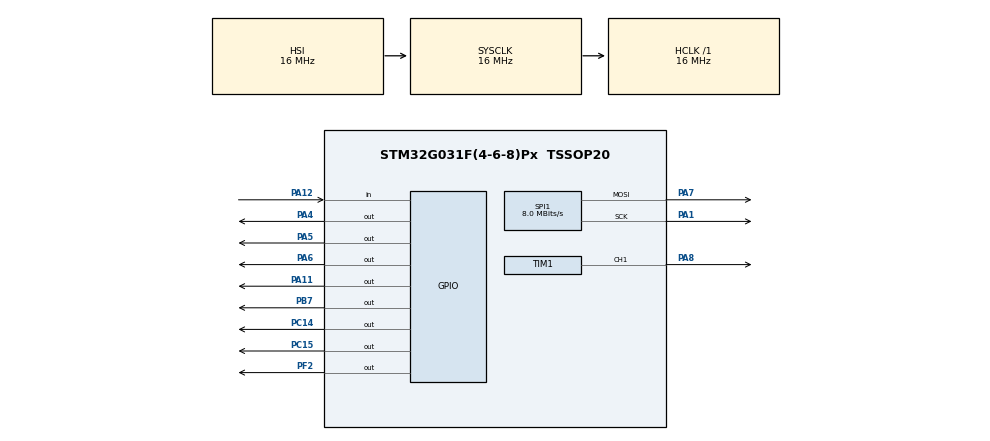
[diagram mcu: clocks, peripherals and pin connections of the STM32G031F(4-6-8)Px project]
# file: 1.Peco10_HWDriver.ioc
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Mcu.Family=STM32G0
Mcu.Name=STM32G031F(4-6-8)Px
Mcu.Package=TSSOP20
NVIC.SPI1_IRQn=true\:0\:0\:false\:false\:true\:true\:true\:true
PA1.Mode=TX_Only_Simplex_Unidirect_Master
PA1.Signal=SPI1_SCK
PA11\ [PA9].Signal=GPIO_Output
PA12\ [PA10].Signal=GPIO_Input
PA14-BOOT0__PA15.StandardMode=true
PA4.Signal=GPIO_Output
PA5.Signal=GPIO_Output
PA6.Signal=GPIO_Output
PA7.Mode=TX_Only_Simplex_Unidirect_Master
PA7.Signal=SPI1_MOSI
PA8.Signal=S_TIM1_CH1
PB0__PB1__PB2__PA8.StandardMode=true
PB3__PB4__PB5__PB6.StandardMode=true
PB7.Signal=GPIO_Output
PB7__PB8.StandardMode=true
PC14-OSC32_IN\ (PC14).Signal=GPIO_Output
PC14-OSC32_IN\ (PC14)__PB9.StandardMode=true
PC15-OSC32_OUT\ (PC15).Signal=GPIO_Output
PF2\ -\ NRST.Signal=GPIO_Output
ProjectManager.HeapSize=0x200
ProjectManager.StackSize=0x400
ProjectManager.TargetToolchain=MDK-ARM V5.32
RCC.AHBFreq_Value=16000000
RCC.CortexFreq_Value=16000000
RCC.EXTERNAL_CLOCK_VALUE=12288000
RCC.HCLKFreq_Value=16000000
RCC.HSE_VALUE=8000000
RCC.HSI_VALUE=16000000
RCC.LSE_VALUE=32768
RCC.SYSCLKFreq_VALUE=16000000
RCC.VCOOutputFreq_Value=128000000
SH.S_TIM1_CH1.0=TIM1_CH1,PWM Generation1 CH1
SPI1.CalculateBaudRate=8.0 MBits/s
SPI1.Direction=SPI_DIRECTION_2LINES
SPI1.Mode=SPI_MODE_MASTER
SPI1.VirtualType=VM_MASTER
TIM1.Channel-PWM\ Generation1\ CH1=TIM_CHANNEL_1
TIM1.Period=999
TIM1.Prescaler=15
TIM1.Pulse-PWM\ Generation1\ CH1=900
TIM2.Prescaler=15
VP_TIM1_VS_ClockSourceINT.Mode=Internal
VP_TIM2_VS_ClockSourceINT.Mode=Internal
board=custom

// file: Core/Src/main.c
/* USER CODE BEGIN Header */
/**
  ******************************************************************************
  * @file           : main.c
  * @brief          : Main program body
  ******************************************************************************
  * @attention
  *
  * Copyright (c) 2022 STMicroelectronics.
  * All rights reserved.
  *
  * This software is licensed under terms that can be found in the LICENSE file
  * in the root directory of this software component.
  * If no LICENSE file comes with this software, it is provided AS-IS.
  *
  ******************************************************************************
  */
/* USER CODE END Header */
#include "main.h"

/* USER CODE BEGIN Includes */
#include "Lcd_character.h"
#include "Lcd_segment.h"
#include "Keypad.h"
#include "Standard.h"
/* USER CODE END Includes */

 SPI_HandleTypeDef hspi1;

TIM_HandleTypeDef htim1;
TIM_HandleTypeDef htim2;

/* USER CODE BEGIN PV */
uint8_t Add_string[]="Address num:";
uint8_t Keypad_string[]="Cur Button:";
uint8_t data0[]="   0,0.0";
uint8_t data1[]="0,00,00";
uint8_t data2[]="1,2.3,456";
/* USER CODE END PV */

void SystemClock_Config(void);
static void MX_GPIO_Init(void);
static void MX_SPI1_Init(void);
static void MX_TIM1_Init(void);
static void MX_TIM2_Init(void);

int main(void)
{

  /* MCU Configuration--------------------------------------------------------*/

  /* Reset of all peripherals, Initializes the Flash interface and the Systick. */
  HAL_Init();

  /* Configure the system clock */
  SystemClock_Config();

  /* Initialize all configured peripherals */
  MX_GPIO_Init();
  MX_SPI1_Init();
  MX_TIM1_Init();
  MX_TIM2_Init();
  /* USER CODE BEGIN 2 */
  uint8_t num[10];
  uint32_t i=0;

  uint8_t key[2];
  Keypad_Button_Type Keypad_status = BUTTON_UNKNOWN;

  uint8_t pDevide_Address[10];
  uint8_t pClear_data[10]="  ";
  uint8_t add,temp;
  temp = 0xff;

  HAL_TIM_Base_Start(&htim2);
  HAL_TIM_PWM_Start(&htim1,TIM_CHANNEL_1);
  Lcd_Init_4bits_Mode();
  Lcd_Segment_Init();

  //Lcd_Segment_Put_Data(data0,0);
  //Lcd_Segment_Put_Data(data1,1);
  //Lcd_Segment_Put_Data(data2,2);
  Lcd_Segment_Put_Indicator(0xf8);
  Lcd_Segment_Display_App();
  Lcd_Put_String(0,0,(uint8_t*)Keypad_string);
  Lcd_Put_String(1,0,(uint8_t*)Add_string);
  //Lcd_Put_String(0,2,(uint8_t*)data);
  /* USER CODE END 2 */

  /* Infinite loop */
  while (1)
  {

    /* USER CODE BEGIN 3 */
    /*Lcd segment test*/
    DecToString(num,i);
    Lcd_Segment_Put_Data(num,0);
    Lcd_Segment_Put_Data(num,1);
    Lcd_Segment_Put_Data(num,2);
    Lcd_Segment_Display_App();

    /*Keypad scaning test*/

    Keypad_status = Keypad_Scan(key);
    if(Keypad_status == KEYPAD_PUSHED)
    {
        Lcd_Put_String(0,strlen((char*)Keypad_string) + 1,(uint8_t*)pClear_data);
        Lcd_Set_Cursor(0,strlen((char*)Keypad_string) + 1);
        Lcd_Put_String(0,strlen((char*)Keypad_string) + 1,(uint8_t*)key);
    }

    /*Switch test*/
    add = Config_Switch_Get_Value();
    if(temp != add)
    {
        DecToString(pDevide_Address,add);
        temp = add;
        Lcd_Put_String(1,strlen((char*)Add_string) + 1,(uint8_t*)pClear_data);
        Lcd_Put_String(1,strlen((char*)Add_string) + 1,(uint8_t*)pDevide_Address);
    }

    mdelay(1);
    i++;
    if(i == 9999999)
        i=0;
  }
  /* USER CODE END 3 */
}

void SystemClock_Config(void)
{
  RCC_OscInitTypeDef RCC_OscInitStruct = {0};
  RCC_ClkInitTypeDef RCC_ClkInitStruct = {0};

  /** Configure the main internal regulator output voltage
  */
  HAL_PWREx_ControlVoltageScaling(PWR_REGULATOR_VOLTAGE_SCALE1);

  /** Initializes the RCC Oscillators according to the specified parameters
  * in the RCC_OscInitTypeDef structure.
  */
  RCC_OscInitStruct.OscillatorType = RCC_OSCILLATORTYPE_HSI;
  RCC_OscInitStruct.HSIState = RCC_HSI_ON;
  RCC_OscInitStruct.HSIDiv = RCC_HSI_DIV1;
  RCC_OscInitStruct.HSICalibrationValue = RCC_HSICALIBRATION_DEFAULT;
  RCC_OscInitStruct.PLL.PLLState = RCC_PLL_NONE;
  if (HAL_RCC_OscConfig(&RCC_OscInitStruct) != HAL_OK)
  {
    Error_Handler();
  }

  /** Initializes the CPU, AHB and APB buses clocks
  */
  RCC_ClkInitStruct.ClockType = RCC_CLOCKTYPE_HCLK|RCC_CLOCKTYPE_SYSCLK
                              |RCC_CLOCKTYPE_PCLK1;
  RCC_ClkInitStruct.SYSCLKSource = RCC_SYSCLKSOURCE_HSI;
  RCC_ClkInitStruct.AHBCLKDivider = RCC_SYSCLK_DIV1;
  RCC_ClkInitStruct.APB1CLKDivider = RCC_HCLK_DIV1;

  if (HAL_RCC_ClockConfig(&RCC_ClkInitStruct, FLASH_LATENCY_0) != HAL_OK)
  {
    Error_Handler();
  }
}

static void MX_SPI1_Init(void)
{

  /* SPI1 parameter configuration*/
  hspi1.Instance = SPI1;
  hspi1.Init.Mode = SPI_MODE_MASTER;
  hspi1.Init.Direction = SPI_DIRECTION_2LINES;
  hspi1.Init.DataSize = SPI_DATASIZE_8BIT;
  hspi1.Init.CLKPolarity = SPI_POLARITY_LOW;
  hspi1.Init.CLKPhase = SPI_PHASE_1EDGE;
  hspi1.Init.NSS = SPI_NSS_SOFT;
  hspi1.Init.BaudRatePrescaler = SPI_BAUDRATEPRESCALER_2;
  hspi1.Init.FirstBit = SPI_FIRSTBIT_MSB;
  hspi1.Init.TIMode = SPI_TIMODE_DISABLE;
  hspi1.Init.CRCCalculation = SPI_CRCCALCULATION_DISABLE;
  hspi1.Init.CRCPolynomial = 7;
  hspi1.Init.CRCLength = SPI_CRC_LENGTH_DATASIZE;
  hspi1.Init.NSSPMode = SPI_NSS_PULSE_ENABLE;
  if (HAL_SPI_Init(&hspi1) != HAL_OK)
  {
    Error_Handler();
  }

}

static void MX_TIM1_Init(void)
{

  TIM_ClockConfigTypeDef sClockSourceConfig = {0};
  TIM_MasterConfigTypeDef sMasterConfig = {0};
  TIM_OC_InitTypeDef sConfigOC = {0};
  TIM_BreakDeadTimeConfigTypeDef sBreakDeadTimeConfig = {0};

  htim1.Instance = TIM1;
  htim1.Init.Prescaler = 15;
  htim1.Init.CounterMode = TIM_COUNTERMODE_UP;
  htim1.Init.Period = 999;
  htim1.Init.ClockDivision = TIM_CLOCKDIVISION_DIV1;
  htim1.Init.RepetitionCounter = 0;
  htim1.Init.AutoReloadPreload = TIM_AUTORELOAD_PRELOAD_DISABLE;
  if (HAL_TIM_Base_Init(&htim1) != HAL_OK)
  {
    Error_Handler();
  }
  sClockSourceConfig.ClockSource = TIM_CLOCKSOURCE_INTERNAL;
  if (HAL_TIM_ConfigClockSource(&htim1, &sClockSourceConfig) != HAL_OK)
  {
    Error_Handler();
  }
  if (HAL_TIM_PWM_Init(&htim1) != HAL_OK)
  {
    Error_Handler();
  }
  sMasterConfig.MasterOutputTrigger = TIM_TRGO_RESET;
  sMasterConfig.MasterOutputTrigger2 = TIM_TRGO2_RESET;
  sMasterConfig.MasterSlaveMode = TIM_MASTERSLAVEMODE_DISABLE;
  if (HAL_TIMEx_MasterConfigSynchronization(&htim1, &sMasterConfig) != HAL_OK)
  {
    Error_Handler();
  }
  sConfigOC.OCMode = TIM_OCMODE_PWM1;
  sConfigOC.Pulse = 900;
  sConfigOC.OCPolarity = TIM_OCPOLARITY_HIGH;
  sConfigOC.OCNPolarity = TIM_OCNPOLARITY_HIGH;
  sConfigOC.OCFastMode = TIM_OCFAST_DISABLE;
  sConfigOC.OCIdleState = TIM_OCIDLESTATE_RESET;
  sConfigOC.OCNIdleState = TIM_OCNIDLESTATE_RESET;
  if (HAL_TIM_PWM_ConfigChannel(&htim1, &sConfigOC, TIM_CHANNEL_1) != HAL_OK)
  {
    Error_Handler();
  }
  sBreakDeadTimeConfig.OffStateRunMode = TIM_OSSR_DISABLE;
  sBreakDeadTimeConfig.OffStateIDLEMode = TIM_OSSI_DISABLE;
  sBreakDeadTimeConfig.LockLevel = TIM_LOCKLEVEL_OFF;
  sBreakDeadTimeConfig.DeadTime = 0;
  sBreakDeadTimeConfig.BreakState = TIM_BREAK_DISABLE;
  sBreakDeadTimeConfig.BreakPolarity = TIM_BREAKPOLARITY_HIGH;
  sBreakDeadTimeConfig.BreakFilter = 0;
  sBreakDeadTimeConfig.BreakAFMode = TIM_BREAK_AFMODE_INPUT;
  sBreakDeadTimeConfig.Break2State = TIM_BREAK2_DISABLE;
  sBreakDeadTimeConfig.Break2Polarity = TIM_BREAK2POLARITY_HIGH;
  sBreakDeadTimeConfig.Break2Filter = 0;
  sBreakDeadTimeConfig.Break2AFMode = TIM_BREAK_AFMODE_INPUT;
  sBreakDeadTimeConfig.AutomaticOutput = TIM_AUTOMATICOUTPUT_DISABLE;
  if (HAL_TIMEx_ConfigBreakDeadTime(&htim1, &sBreakDeadTimeConfig) != HAL_OK)
  {
    Error_Handler();
  }
  HAL_TIM_MspPostInit(&htim1);

}

static void MX_TIM2_Init(void)
{

  TIM_ClockConfigTypeDef sClockSourceConfig = {0};
  TIM_MasterConfigTypeDef sMasterConfig = {0};

  htim2.Instance = TIM2;
  htim2.Init.Prescaler = 15;
  htim2.Init.CounterMode = TIM_COUNTERMODE_UP;
  htim2.Init.Period = 4294967295;
  htim2.Init.ClockDivision = TIM_CLOCKDIVISION_DIV1;
  htim2.Init.AutoReloadPreload = TIM_AUTORELOAD_PRELOAD_DISABLE;
  if (HAL_TIM_Base_Init(&htim2) != HAL_OK)
  {
    Error_Handler();
  }
  sClockSourceConfig.ClockSource = TIM_CLOCKSOURCE_INTERNAL;
  if (HAL_TIM_ConfigClockSource(&htim2, &sClockSourceConfig) != HAL_OK)
  {
    Error_Handler();
  }
  sMasterConfig.MasterOutputTrigger = TIM_TRGO_RESET;
  sMasterConfig.MasterSlaveMode = TIM_MASTERSLAVEMODE_DISABLE;
  if (HAL_TIMEx_MasterConfigSynchronization(&htim2, &sMasterConfig) != HAL_OK)
  {
    Error_Handler();
  }

}

static void MX_GPIO_Init(void)
{
  GPIO_InitTypeDef GPIO_InitStruct = {0};

  /* GPIO Ports Clock Enable */
  __HAL_RCC_GPIOB_CLK_ENABLE();
  __HAL_RCC_GPIOC_CLK_ENABLE();
  __HAL_RCC_GPIOF_CLK_ENABLE();
  __HAL_RCC_GPIOA_CLK_ENABLE();

  /*Configure GPIO pin Output Level */
  HAL_GPIO_WritePin(GPIOB, GPIO_PIN_7|GPIO_PIN_3, GPIO_PIN_RESET);

  /*Configure GPIO pin Output Level */
  HAL_GPIO_WritePin(GPIOC, GPIO_PIN_14|GPIO_PIN_15, GPIO_PIN_RESET);

  /*Configure GPIO pin Output Level */
  HAL_GPIO_WritePin(GPIOF, GPIO_PIN_2, GPIO_PIN_RESET);

  /*Configure GPIO pin Output Level */
  HAL_GPIO_WritePin(GPIOA, GPIO_PIN_4|GPIO_PIN_5|GPIO_PIN_6|GPIO_PIN_11, GPIO_PIN_RESET);

  /*Configure GPIO pins : PB7 PB3 */
  GPIO_InitStruct.Pin = GPIO_PIN_7|GPIO_PIN_3;
  GPIO_InitStruct.Mode = GPIO_MODE_OUTPUT_PP;
  GPIO_InitStruct.Pull = GPIO_NOPULL;
  GPIO_InitStruct.Speed = GPIO_SPEED_FREQ_LOW;
  HAL_GPIO_Init(GPIOB, &GPIO_InitStruct);

  /*Configure GPIO pins : PC14 PC15 */
  GPIO_InitStruct.Pin = GPIO_PIN_14|GPIO_PIN_15;
  GPIO_InitStruct.Mode = GPIO_MODE_OUTPUT_PP;
  GPIO_InitStruct.Pull = GPIO_NOPULL;
  GPIO_InitStruct.Speed = GPIO_SPEED_FREQ_LOW;
  HAL_GPIO_Init(GPIOC, &GPIO_InitStruct);

  /*Configure GPIO pin : PF2 */
  GPIO_InitStruct.Pin = GPIO_PIN_2;
  GPIO_InitStruct.Mode = GPIO_MODE_OUTPUT_PP;
  GPIO_InitStruct.Pull = GPIO_NOPULL;
  GPIO_InitStruct.Speed = GPIO_SPEED_FREQ_LOW;
  HAL_GPIO_Init(GPIOF, &GPIO_InitStruct);

  /*Configure GPIO pins : PA4 PA5 PA6 PA11 */
  GPIO_InitStruct.Pin = GPIO_PIN_4|GPIO_PIN_5|GPIO_PIN_6|GPIO_PIN_11;
  GPIO_InitStruct.Mode = GPIO_MODE_OUTPUT_PP;
  GPIO_InitStruct.Pull = GPIO_NOPULL;
  GPIO_InitStruct.Speed = GPIO_SPEED_FREQ_LOW;
  HAL_GPIO_Init(GPIOA, &GPIO_InitStruct);

  /*Configure GPIO pin : PA12 */
  GPIO_InitStruct.Pin = GPIO_PIN_12;
  GPIO_InitStruct.Mode = GPIO_MODE_INPUT;
  GPIO_InitStruct.Pull = GPIO_NOPULL;
  HAL_GPIO_Init(GPIOA, &GPIO_InitStruct);

}

void Error_Handler(void)
{
  __disable_irq();
  while (1)
  {
  }
}
